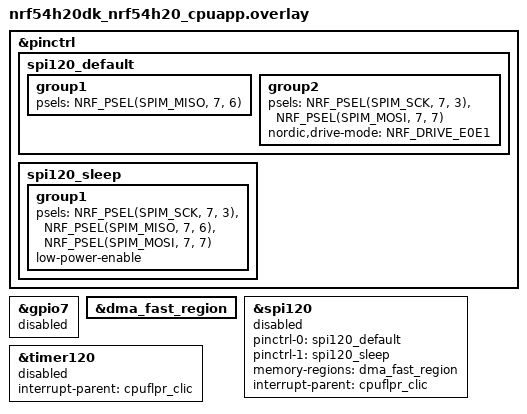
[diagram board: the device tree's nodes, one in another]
/*
 * Copyright (c) 2026 Nordic Semiconductor ASA
 *
 * SPDX-License-Identifier: LicenseRef-Nordic-5-Clause
 */

&pinctrl {
	spi120_default: spi120_default {
		group1 {
			psels = <NRF_PSEL(SPIM_MISO, 7, 6)>;
		};

		group2 {
			psels = <NRF_PSEL(SPIM_SCK, 7, 3)>,
				<NRF_PSEL(SPIM_MOSI, 7, 7)>;
			nordic,drive-mode = <NRF_DRIVE_E0E1>;
		};
	};

	spi120_sleep: spi120_sleep {
		group1 {
			psels = <NRF_PSEL(SPIM_SCK, 7, 3)>,
				<NRF_PSEL(SPIM_MISO, 7, 6)>,
				<NRF_PSEL(SPIM_MOSI, 7, 7)>;
			low-power-enable;
		};
	};
};

&gpio7 {
	status = "reserved";
};

&dma_fast_region {
	status = "okay";
};

&spi120 {
	status = "reserved";
	pinctrl-0 = <&spi120_default>;
	pinctrl-1 = <&spi120_sleep>;
	pinctrl-names = "default", "sleep";
	memory-regions = <&dma_fast_region>;
	interrupt-parent = <&cpuflpr_clic>;
};

&timer120 {
	status = "reserved";
	interrupt-parent = <&cpuflpr_clic>;
};
